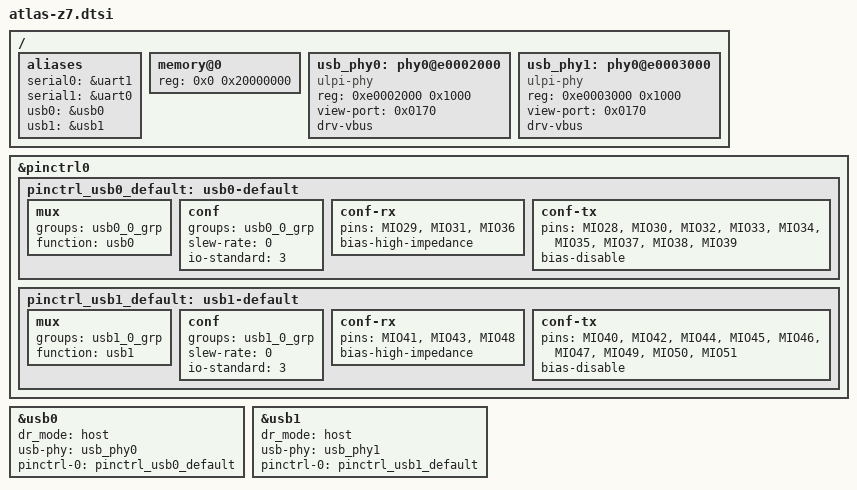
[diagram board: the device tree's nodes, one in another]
/ {
    aliases {
        /* uart1 is console */
        serial0 = &uart1;
        serial1 = &uart0;
		usb0 = &usb0;
		usb1 = &usb1;
    };

	memory@0 {
		device_type = "memory";
		reg = <0x0 0x20000000>;
	};

	usb_phy0: phy0@e0002000 {
		compatible = "ulpi-phy";
		#phy-cells = <0>;
		reg = <0xe0002000 0x1000>;
		view-port = <0x0170>;
		drv-vbus;
	};

	usb_phy1: phy0@e0003000 {
		compatible = "ulpi-phy";
		#phy-cells = <0>;
		reg = <0xe0003000 0x1000>;
		view-port = <0x0170>;
		drv-vbus;
	};
};

&pinctrl0 {
	pinctrl_usb0_default: usb0-default {
		mux {
			groups = "usb0_0_grp";
			function = "usb0";
		};

		conf {
			groups = "usb0_0_grp";
			slew-rate = <0>;
			io-standard = <3>;
		};

		conf-rx {
			pins = "MIO29", "MIO31", "MIO36";
			bias-high-impedance;
		};

		conf-tx {
			pins = "MIO28", "MIO30", "MIO32", "MIO33", "MIO34",
			       "MIO35", "MIO37", "MIO38", "MIO39";
			bias-disable;
		};
	};

	pinctrl_usb1_default: usb1-default {
		mux {
			groups = "usb1_0_grp";
			function = "usb1";
		};

		conf {
			groups = "usb1_0_grp";
			slew-rate = <0>;
			io-standard = <3>;
		};

		conf-rx {
			pins = "MIO41", "MIO43", "MIO48";
			bias-high-impedance;
		};

		conf-tx {
			pins = "MIO40", "MIO42", "MIO44", "MIO45", "MIO46",
			       "MIO47", "MIO49", "MIO50", "MIO51";
			bias-disable;
		};
	};
};

&usb0 {
	status = "okay";
	dr_mode = "host";
	usb-phy = <&usb_phy0>;
	pinctrl-names = "default";
	pinctrl-0 = <&pinctrl_usb0_default>;
};

&usb1 {
	status = "okay";
	dr_mode = "host";
	usb-phy = <&usb_phy1>;
	pinctrl-names = "default";
	pinctrl-0 = <&pinctrl_usb1_default>;
};

